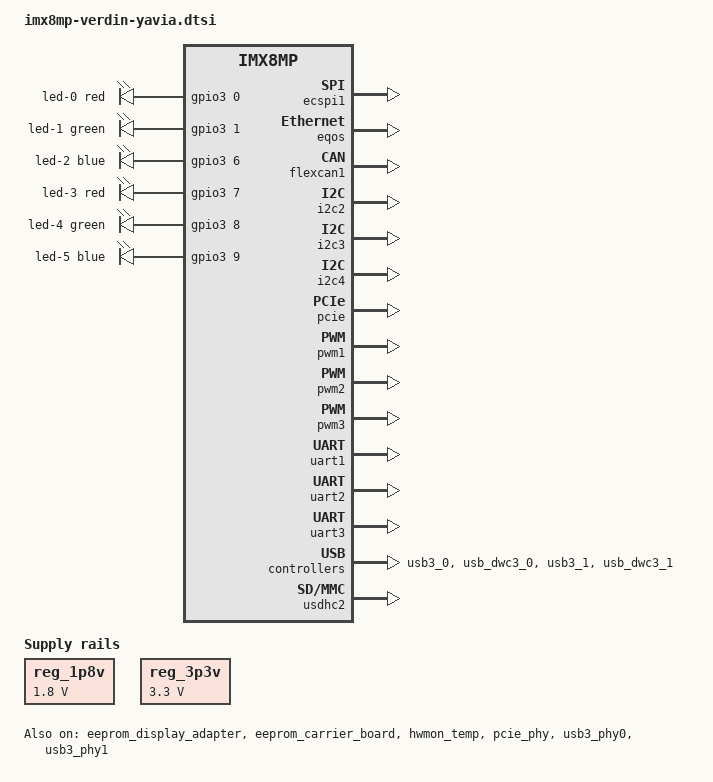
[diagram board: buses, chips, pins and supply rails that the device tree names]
#include <dt-bindings/leds/common.h>
/ {
	reg_1p8v: regulator-1p8v {
		compatible = "regulator-fixed";
		regulator-max-microvolt = <1800000>;
		regulator-min-microvolt = <1800000>;
		regulator-name = "+V1.8_SW";
	};
	reg_3p3v: regulator-3p3v {
		compatible = "regulator-fixed";
		regulator-max-microvolt = <3300000>;
		regulator-min-microvolt = <3300000>;
		regulator-name = "+V3.3_SW";
	};
	leds {
		compatible = "gpio-leds";
		pinctrl-names = "default";
		pinctrl-0 = <&pinctrl_leds_yavia>;
		led-0 {
			color = <LED_COLOR_ID_RED>;
			function = LED_FUNCTION_DEBUG;
			function-enumerator = <1>;
			gpios = <&gpio3 0 GPIO_ACTIVE_HIGH>;
		};
		led-1 {
			color = <LED_COLOR_ID_GREEN>;
			function = LED_FUNCTION_DEBUG;
			function-enumerator = <1>;
			gpios = <&gpio3 1 GPIO_ACTIVE_HIGH>;
		};
		led-2 {
			color = <LED_COLOR_ID_BLUE>;
			function = LED_FUNCTION_DEBUG;
			function-enumerator = <1>;
			gpios = <&gpio3 6 GPIO_ACTIVE_HIGH>;
		};
		led-3 {
			color = <LED_COLOR_ID_RED>;
			function = LED_FUNCTION_DEBUG;
			function-enumerator = <2>;
			gpios = <&gpio3 7 GPIO_ACTIVE_HIGH>;
		};
		led-4 {
			color = <LED_COLOR_ID_GREEN>;
			function = LED_FUNCTION_DEBUG;
			function-enumerator = <2>;
			gpios = <&gpio3 8 GPIO_ACTIVE_HIGH>;
		};
		led-5 {
			color = <LED_COLOR_ID_BLUE>;
			function = LED_FUNCTION_DEBUG;
			function-enumerator = <2>;
			gpios = <&gpio3 9 GPIO_ACTIVE_HIGH>;
		};
	};
};
&backlight {
	power-supply = <&reg_3p3v>;
};
&ecspi1 {
	status = "okay";
};
&eeprom_display_adapter {
	status = "okay";
};
&eeprom_carrier_board {
	status = "okay";
};
&eqos {
	status = "okay";
};
&flexcan1 {
	status = "okay";
};
&hwmon_temp {
	status = "okay";
};
&i2c2 {
	status = "okay";
};
&i2c3 {
	status = "okay";
};
&i2c4 {
	status = "okay";
};
&pcie {
	status = "okay";
};
&pcie_phy {
	status = "okay";
};
&pwm1 {
	status = "okay";
};
&pwm2 {
	status = "okay";
};
&pwm3 {
	status = "okay";
};
&reg_usdhc2_vmmc {
	vin-supply = <&reg_3p3v>;
};
&uart1 {
	status = "okay";
};
&uart2 {
	status = "okay";
};
&uart3 {
	status = "okay";
};
&usb3_phy0 {
	status = "okay";
};
&usb3_0 {
	status = "okay";
};
&usb_dwc3_0 {
	status = "okay";
};
&usb3_phy1 {
	status = "okay";
};
&usb3_1 {
	status = "okay";
};
&usb_dwc3_1 {
	status = "okay";
};
&usdhc2 {
	status = "okay";
};
&iomuxc {
	pinctrl_leds_yavia: ledsyaviagrp {
		fsl,pins = <
			MX8MP_IOMUXC_NAND_ALE__GPIO3_IO00	0x106	 
			MX8MP_IOMUXC_NAND_CE0_B__GPIO3_IO01	0x106	 
			MX8MP_IOMUXC_NAND_DATA00__GPIO3_IO06	0x106	 
			MX8MP_IOMUXC_NAND_DATA01__GPIO3_IO07	0x106	 
			MX8MP_IOMUXC_NAND_DATA02__GPIO3_IO08	0x106	 
			MX8MP_IOMUXC_NAND_DATA03__GPIO3_IO09	0x106	 
		>;
	};
	pinctrl_gpios_ext_yavia: gpiosextyaviagrp {
		fsl,pins = <
			MX8MP_IOMUXC_NAND_CE1_B__GPIO3_IO02	0x106	 
			MX8MP_IOMUXC_NAND_DQS__GPIO3_IO14	0x106	 
		>;
	};
};
